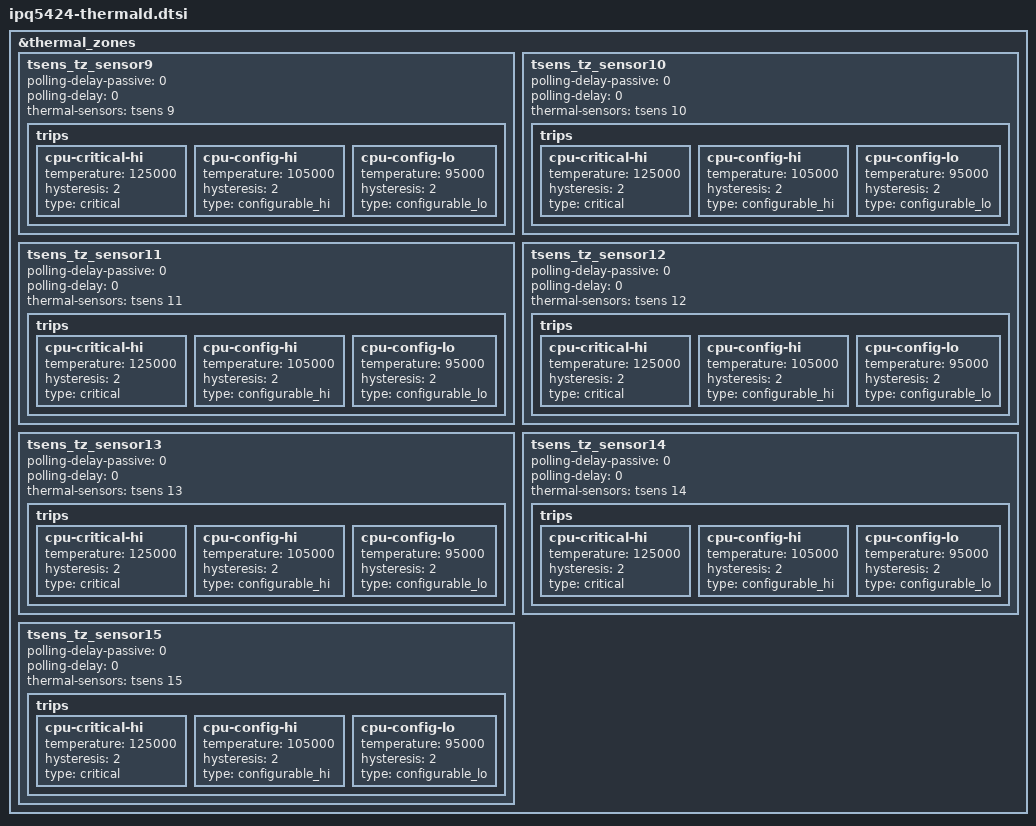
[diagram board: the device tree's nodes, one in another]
/*
 * Copyright (c) 2019-2021, The Linux Foundation. All rights reserved.
 *
 * Copyright (c) 2022-2024 Qualcomm Innovation Center, Inc. All rights reserved.
 *
 * Permission to use, copy, modify, and/or distribute this software for any
 * purpose with or without fee is hereby granted, provided that the above
 * copyright notice and this permission notice appear in all copies.
 *
 * THE SOFTWARE IS PROVIDED "AS IS" AND THE AUTHOR DISCLAIMS ALL WARRANTIES
 * WITH REGARD TO THIS SOFTWARE INCLUDING ALL IMPLIED WARRANTIES OF
 * MERCHANTABILITY AND FITNESS. IN NO EVENT SHALL THE AUTHOR BE LIABLE FOR
 * ANY SPECIAL, DIRECT, INDIRECT, OR CONSEQUENTIAL DAMAGES OR ANY DAMAGES
 * WHATSOEVER RESULTING FROM LOSS OF USE, DATA OR PROFITS, WHETHER IN AN
 * ACTION OF CONTRACT, NEGLIGENCE OR OTHER TORTIOUS ACTION, ARISING OUT OF
 * OR IN CONNECTION WITH THE USE OR PERFORMANCE OF THIS SOFTWARE.
 */

&thermal_zones {
	/delete-node/ cpu0-thermal;
	/delete-node/ cpu1-thermal;
	/delete-node/ cpu2-thermal;
	/delete-node/ cpu3-thermal;
	/delete-node/ wcss-tile2-thermal;
	/delete-node/ wcss-tile3-thermal;
	/delete-node/ top-glue-thermal;

	tsens_tz_sensor9 {
		polling-delay-passive = <0>;
		polling-delay = <0>;
		thermal-sensors = <&tsens 9>;

		trips {
			cpu-critical-hi {
				temperature = <125000>;
				hysteresis = <2>;
				type = "critical";
			};

			cpu-config-hi {
				temperature = <105000>;
				hysteresis = <2>;
				type = "configurable_hi";
			};

			cpu-config-lo {
				temperature = <95000>;
				hysteresis = <2>;
				type = "configurable_lo";
			};
		};
	};

	tsens_tz_sensor10 {
		polling-delay-passive = <0>;
		polling-delay = <0>;
		thermal-sensors = <&tsens 10>;

		trips {
			cpu-critical-hi {
				temperature = <125000>;
				hysteresis = <2>;
				type = "critical";
			};

			cpu-config-hi {
				temperature = <105000>;
				hysteresis = <2>;
				type = "configurable_hi";
			};

			cpu-config-lo {
				temperature = <95000>;
				hysteresis = <2>;
				type = "configurable_lo";
			};
		};
	};

	tsens_tz_sensor11 {
		polling-delay-passive = <0>;
		polling-delay = <0>;
		thermal-sensors = <&tsens 11>;

		trips {
			cpu-critical-hi {
				temperature = <125000>;
				hysteresis = <2>;
				type = "critical";
			};

			cpu-config-hi {
				temperature = <105000>;
				hysteresis = <2>;
				type = "configurable_hi";
			};

			cpu-config-lo {
				temperature = <95000>;
				hysteresis = <2>;
				type = "configurable_lo";
			};
		};
	};

	tsens_tz_sensor12 {
		polling-delay-passive = <0>;
		polling-delay = <0>;
		thermal-sensors = <&tsens 12>;

		trips {
			cpu-critical-hi {
				temperature = <125000>;
				hysteresis = <2>;
				type = "critical";
			};

			cpu-config-hi {
				temperature = <105000>;
				hysteresis = <2>;
				type = "configurable_hi";
			};

			cpu-config-lo {
				temperature = <95000>;
				hysteresis = <2>;
				type = "configurable_lo";
			};
		};
	};

	tsens_tz_sensor13 {
		polling-delay-passive = <0>;
		polling-delay = <0>;
		thermal-sensors = <&tsens 13>;

		trips {
			cpu-critical-hi {
				temperature = <125000>;
				hysteresis = <2>;
				type = "critical";
			};

			cpu-config-hi {
				temperature = <105000>;
				hysteresis = <2>;
				type = "configurable_hi";
			};

			cpu-config-lo {
				temperature = <95000>;
				hysteresis = <2>;
				type = "configurable_lo";
			};
		};
	};

	tsens_tz_sensor14 {
		polling-delay-passive = <0>;
		polling-delay = <0>;
		thermal-sensors = <&tsens 14>;

		trips {
			cpu-critical-hi {
				temperature = <125000>;
				hysteresis = <2>;
				type = "critical";
			};

			cpu-config-hi {
				temperature = <105000>;
				hysteresis = <2>;
				type = "configurable_hi";
			};

			cpu-config-lo {
				temperature = <95000>;
				hysteresis = <2>;
				type = "configurable_lo";
			};
		};
	};

	tsens_tz_sensor15 {
		polling-delay-passive = <0>;
		polling-delay = <0>;
		thermal-sensors = <&tsens 15>;

		trips {
			cpu-critical-hi {
				temperature = <125000>;
				hysteresis = <2>;
				type = "critical";
			};

			cpu-config-hi {
				temperature = <105000>;
				hysteresis = <2>;
				type = "configurable_hi";
			};

			cpu-config-lo {
				temperature = <95000>;
				hysteresis = <2>;
				type = "configurable_lo";
			};
		};
	};
};
